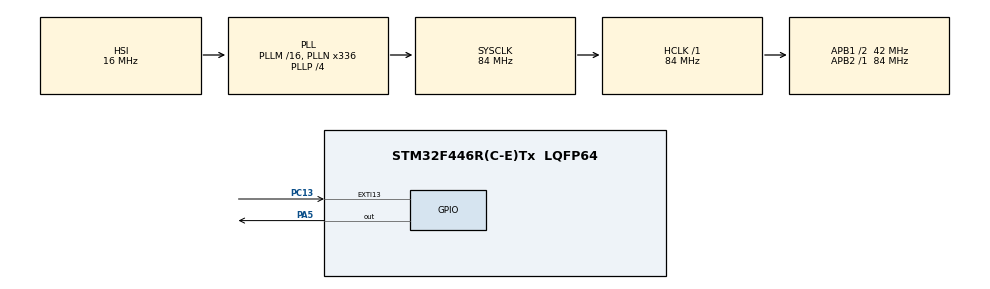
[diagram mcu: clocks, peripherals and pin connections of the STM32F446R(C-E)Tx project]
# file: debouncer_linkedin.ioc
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Mcu.Family=STM32F4
Mcu.Name=STM32F446R(C-E)Tx
Mcu.Package=LQFP64
NUCLEO-F446RE.BUTTON=1
NUCLEO-F446RE.LD1=true
NVIC.EXTI15_10_IRQn=true\:0\:0\:false\:false\:true\:false\:true\:true
NVIC.PriorityGroup=NVIC_PRIORITYGROUP_0
NVIC.TIM2_IRQn=true\:0\:0\:false\:false\:true\:true\:true\:true
PA13.GPIO_Label=TMS
PA13.Signal=SYS_JTMS-SWDIO
PA14.GPIO_Label=TCK
PA14.Signal=SYS_JTCK-SWCLK
PA2.GPIO_Label=USART_TX
PA2.Signal=USART2_TX
PA3.GPIO_Label=USART_RX
PA3.Signal=USART2_RX
PA5.Signal=GPIO_Output
PB3.GPIO_Label=SWO
PB3.Signal=SYS_JTDO-SWO
PC13.GPIO_ModeDefaultEXTI=GPIO_MODE_IT_FALLING
PC13.Signal=GPXTI13
PC14-OSC32_IN.Signal=RCC_OSC32_IN
PC15-OSC32_OUT.Signal=RCC_OSC32_OUT
PH0-OSC_IN.Signal=RCC_OSC_IN
PH1-OSC_OUT.Signal=RCC_OSC_OUT
ProjectManager.HeapSize=0x200
ProjectManager.StackSize=0x400
ProjectManager.TargetToolchain=STM32CubeIDE
RCC.AHBFreq_Value=84000000
RCC.APB1CLKDivider=RCC_HCLK_DIV2
RCC.APB1Freq_Value=42000000
RCC.APB1TimFreq_Value=84000000
RCC.APB2Freq_Value=84000000
RCC.APB2TimFreq_Value=84000000
RCC.CortexFreq_Value=84000000
RCC.FLatency-AdvancedSettings=FLASH_LATENCY_2
RCC.HCLKFreq_Value=84000000
RCC.HSE_VALUE=8000000
RCC.HSI_VALUE=16000000
RCC.LSE_VALUE=32768
RCC.PLLN=336
RCC.PLLP=RCC_PLLP_DIV4
RCC.SYSCLKFreq_VALUE=84000000
RCC.SYSCLKSource=RCC_SYSCLKSOURCE_PLLCLK
RCC.USBFreq_Value=168000000
RCC.VCOOutputFreq_Value=336000000
TIM2.Period=999
TIM2.Prescaler=83
VP_NUCLEO-F446RE_VS_BSP_COMMON.Mode=COMMON
VP_TIM2_VS_ClockSourceINT.Mode=Internal
board=NUCLEO-F446RE

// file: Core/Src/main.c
/* USER CODE BEGIN Header */
/**
  ******************************************************************************
  * @file           : main.c
  * @brief          : Main program body
  ******************************************************************************
  */
/* USER CODE END Header */
#include "main.h"

TIM_HandleTypeDef htim2;

/* USER CODE BEGIN PV */
volatile uint8_t debounce_busy = 0;  // "I'm busy, ignore more edges"
volatile uint32_t press_count = 0;   // Counts valid presses
/* USER CODE END PV */

void SystemClock_Config(void);
static void MX_GPIO_Init(void);
static void MX_TIM2_Init(void);

int main(void)
{

  /* MCU Configuration--------------------------------------------------------*/
  HAL_Init();

  /* Configure the system clock */
  SystemClock_Config();

  /* Initialize all configured peripherals */
  MX_GPIO_Init();
  MX_TIM2_Init();

  /* Initialize leds */
  BSP_LED_Init(LED2);

  /* Initialize USER push-button, triggers an interrupt each time it is pressed */
  BSP_PB_Init(BUTTON_USER, BUTTON_MODE_EXTI);

  /* Infinite loop */
  while (1)
  {

    /* USER CODE BEGIN 3 */
    // The main loop notices a new valid press and toggles the LED
    static uint32_t last_count = 0;
    if (press_count != last_count)
    {
      last_count = press_count;
      HAL_GPIO_TogglePin(GPIOA, GPIO_PIN_5);  // LD2 on NUCLEO-F446RE
    }
  }
  /* USER CODE END 3 */
}

void SystemClock_Config(void)
{
  RCC_OscInitTypeDef RCC_OscInitStruct = {0};
  RCC_ClkInitTypeDef RCC_ClkInitStruct = {0};

  __HAL_RCC_PWR_CLK_ENABLE();
  __HAL_PWR_VOLTAGESCALING_CONFIG(PWR_REGULATOR_VOLTAGE_SCALE3);

  RCC_OscInitStruct.OscillatorType = RCC_OSCILLATORTYPE_HSI;
  RCC_OscInitStruct.HSIState = RCC_HSI_ON;
  RCC_OscInitStruct.HSICalibrationValue = RCC_HSICALIBRATION_DEFAULT;
  RCC_OscInitStruct.PLL.PLLState = RCC_PLL_ON;
  RCC_OscInitStruct.PLL.PLLSource = RCC_PLLSOURCE_HSI;
  RCC_OscInitStruct.PLL.PLLM = 16;
  RCC_OscInitStruct.PLL.PLLN = 336;
  RCC_OscInitStruct.PLL.PLLP = RCC_PLLP_DIV4;
  RCC_OscInitStruct.PLL.PLLQ = 2;
  RCC_OscInitStruct.PLL.PLLR = 2;
  if (HAL_RCC_OscConfig(&RCC_OscInitStruct) != HAL_OK)
  {
    Error_Handler();
  }

  RCC_ClkInitStruct.ClockType = RCC_CLOCKTYPE_HCLK|RCC_CLOCKTYPE_SYSCLK
                              |RCC_CLOCKTYPE_PCLK1|RCC_CLOCKTYPE_PCLK2;
  RCC_ClkInitStruct.SYSCLKSource = RCC_SYSCLKSOURCE_PLLCLK;
  RCC_ClkInitStruct.AHBCLKDivider = RCC_SYSCLK_DIV1;
  RCC_ClkInitStruct.APB1CLKDivider = RCC_HCLK_DIV2;
  RCC_ClkInitStruct.APB2CLKDivider = RCC_HCLK_DIV1;

  if (HAL_RCC_ClockConfig(&RCC_ClkInitStruct, FLASH_LATENCY_2) != HAL_OK)
  {
    Error_Handler();
  }
}

static void MX_TIM2_Init(void)
{

  TIM_ClockConfigTypeDef sClockSourceConfig = {0};
  TIM_MasterConfigTypeDef sMasterConfig = {0};

  htim2.Instance = TIM2;
  htim2.Init.Prescaler = 83;      // 84 MHz / 84 = 1 MHz, so 1 tick = 1 microsecond
  htim2.Init.CounterMode = TIM_COUNTERMODE_UP;
  htim2.Init.Period = 999;        // 1000 ticks = 1 ms overflow
  htim2.Init.ClockDivision = TIM_CLOCKDIVISION_DIV1;
  htim2.Init.AutoReloadPreload = TIM_AUTORELOAD_PRELOAD_DISABLE;
  if (HAL_TIM_Base_Init(&htim2) != HAL_OK)
  {
    Error_Handler();
  }
  sClockSourceConfig.ClockSource = TIM_CLOCKSOURCE_INTERNAL;
  if (HAL_TIM_ConfigClockSource(&htim2, &sClockSourceConfig) != HAL_OK)
  {
    Error_Handler();
  }
  sMasterConfig.MasterOutputTrigger = TIM_TRGO_RESET;
  sMasterConfig.MasterSlaveMode = TIM_MASTERSLAVEMODE_DISABLE;
  if (HAL_TIMEx_MasterConfigSynchronization(&htim2, &sMasterConfig) != HAL_OK)
  {
    Error_Handler();
  }
}

static void MX_GPIO_Init(void)
{
  GPIO_InitTypeDef GPIO_InitStruct = {0};

  /* GPIO Ports Clock Enable */
  __HAL_RCC_GPIOC_CLK_ENABLE();
  __HAL_RCC_GPIOH_CLK_ENABLE();
  __HAL_RCC_GPIOA_CLK_ENABLE();
  __HAL_RCC_GPIOB_CLK_ENABLE();

  /*Configure GPIO pin Output Level */
  HAL_GPIO_WritePin(GPIOA, GPIO_PIN_5, GPIO_PIN_RESET);

  /*Configure GPIO pin : PC13 */
  GPIO_InitStruct.Pin = GPIO_PIN_13;
  GPIO_InitStruct.Mode = GPIO_MODE_IT_RISING;
  GPIO_InitStruct.Pull = GPIO_NOPULL;
  HAL_GPIO_Init(GPIOC, &GPIO_InitStruct);

  /*Configure GPIO pins : USART_TX_Pin USART_RX_Pin */
  GPIO_InitStruct.Pin = USART_TX_Pin|USART_RX_Pin;
  GPIO_InitStruct.Mode = GPIO_MODE_AF_PP;
  GPIO_InitStruct.Pull = GPIO_NOPULL;
  GPIO_InitStruct.Speed = GPIO_SPEED_FREQ_VERY_HIGH;
  GPIO_InitStruct.Alternate = GPIO_AF7_USART2;
  HAL_GPIO_Init(GPIOA, &GPIO_InitStruct);

  /*Configure GPIO pin : PA5 */
  GPIO_InitStruct.Pin = GPIO_PIN_5;
  GPIO_InitStruct.Mode = GPIO_MODE_OUTPUT_PP;
  GPIO_InitStruct.Pull = GPIO_NOPULL;
  GPIO_InitStruct.Speed = GPIO_SPEED_FREQ_LOW;
  HAL_GPIO_Init(GPIOA, &GPIO_InitStruct);

  /* EXTI interrupt init*/
  HAL_NVIC_SetPriority(EXTI15_10_IRQn, 1, 0);
  HAL_NVIC_EnableIRQ(EXTI15_10_IRQn);

}

/* USER CODE BEGIN 4 */

// 1. Button interrupt: fires on the button edge
void HAL_GPIO_EXTI_Callback(uint16_t GPIO_Pin)
{
  if (GPIO_Pin == GPIO_PIN_13)
  {
    if (!debounce_busy)                    // Only act if we are not already waiting
    {
      debounce_busy = 1;                   // Set the busy flag
      __HAL_TIM_SET_COUNTER(&htim2, 0);    // Reset the timer counter
      HAL_TIM_Base_Start_IT(&htim2);       // Start the 1 ms timer interrupt
    }
  }
}

// 2. Timer interrupt: fires every 1 ms once started
void HAL_TIM_PeriodElapsedCallback(TIM_HandleTypeDef *htim)
{
  if (htim->Instance == TIM2)
  {
    if (debounce_busy)
    {
      static uint8_t tick_count = 0;
      tick_count++;

      if (tick_count >= 20)                // 20 ms have passed
      {
        tick_count = 0;                    // Reset for next time
        HAL_TIM_Base_Stop_IT(&htim2);      // Stop the timer

        // Final check: is the button STILL pressed? (pin is LOW)
        if (HAL_GPIO_ReadPin(GPIOC, GPIO_PIN_13) == GPIO_PIN_RESET)
        {
          press_count++;                   // Valid press, count it
        }

        debounce_busy = 0;                 // Free again, ready for the next press
      }
    }
  }
}

/* USER CODE END 4 */

void Error_Handler(void)
{
  __disable_irq();
  while (1)
  {
  }
}
